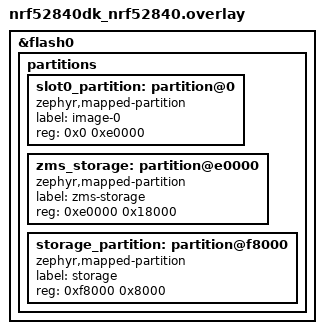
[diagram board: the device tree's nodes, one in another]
/*
 * Flash partition layout migrated from Partition Manager
 * (pm_static_nrf52840dk_nrf52840.yml) to devicetree.
 *
 * Layout (matches the previous pm_static configuration):
 *   image-0 (app): 0x0      - 0xE0000
 *   zms-storage:   0xE0000  - 0xF8000
 *   storage:       0xF8000  - 0x100000
 */

/* Remove the board default partition layout (mcuboot/slot0/slot1/storage). */
/delete-node/ &boot_partition;
/delete-node/ &slot0_partition;
/delete-node/ &slot1_partition;
/delete-node/ &storage_partition;

&flash0 {
	partitions {
		slot0_partition: partition@0 {
			compatible = "zephyr,mapped-partition";
			label = "image-0";
			reg = <0x0 0xe0000>;
		};

		zms_storage: partition@e0000 {
			compatible = "zephyr,mapped-partition";
			label = "zms-storage";
			reg = <0xe0000 0x18000>;
		};

		storage_partition: partition@f8000 {
			compatible = "zephyr,mapped-partition";
			label = "storage";
			reg = <0xf8000 0x8000>;
		};
	};
};
